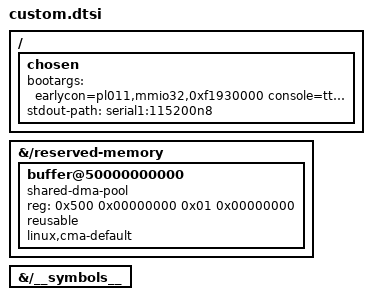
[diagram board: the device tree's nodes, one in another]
/ {
        chosen {
                bootargs = "earlycon=pl011,mmio32,0xf1930000 console=ttyAMA1,115200";
                stdout-path = "serial1:115200n8";
        };
  };
  &{/reserved-memory} {
		
		/delete-node/ cma_reserved@0840000000;
		/delete-node/ cma_reserved@50000000000;
		/delete-node/ cma_reserved@60000000000;

		buffer@50000000000 {
			reg = <0x500 0x00000000 0x01 0x00000000>;
			compatible = "shared-dma-pool";
			reusable;
			linux,cma-default;
		};

  };

  &{/__symbols__} {
		/delete-property/ cma_reserved_0840000000;
		/delete-property/ cma_reserved_50000000000;
		/delete-property/ cma_reserved_60000000000;
  };
